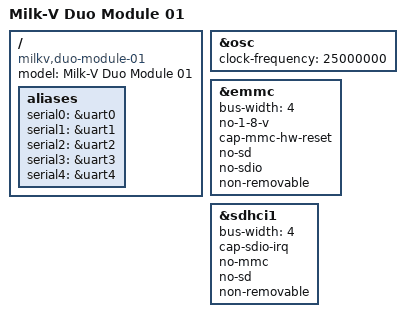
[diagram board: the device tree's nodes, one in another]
// SPDX-License-Identifier: (GPL-2.0 OR MIT)

#include <dt-bindings/pinctrl/pinctrl-sg2000.h>
#include "sg2000.dtsi"

/ {
	model = "Milk-V Duo Module 01";
	compatible = "milkv,duo-module-01", "sophgo,sg2000";

	aliases {
		serial0 = &uart0;
		serial1 = &uart1;
		serial2 = &uart2;
		serial3 = &uart3;
		serial4 = &uart4;
	};
};

&osc {
	clock-frequency = <25000000>;
};

&emmc {
	bus-width = <4>;
	no-1-8-v;
	cap-mmc-hw-reset;
	no-sd;
	no-sdio;
	non-removable;
	status = "okay";
};

/* Wi-Fi */
&sdhci1 {
	bus-width = <4>;
	cap-sdio-irq;
	no-mmc;
	no-sd;
	non-removable;
};
